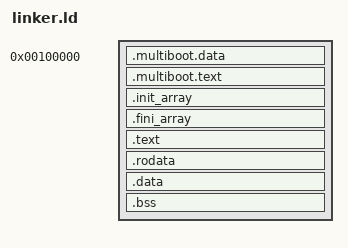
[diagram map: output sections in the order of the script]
ENTRY(_start)

SECTIONS
{
    . = 0x00100000;

    _kernel_start = .;
    .multiboot.data : {
        *(.multiboot.data)
    }

    .multiboot.text : {
        *(.multiboot.text)
    }

    .init_array : AT (ADDR(.init_array) - 0xC0000000)
    {
        crti.o(.init_array)
        KEEP (*(SORT(EXCLUDE_FILE(crti.o crtn.o) .init_array.*)))
        KEEP (*(EXCLUDE_FILE(crti.o crtn.o) .init_array))
        crtn.o(.init_array)
    }

    .fini_array : AT (ADDR(.fini_array) - 0xC0000000)
    {
        crti.o(.fini_array)
        KEEP (*(SORT(EXCLUDE_FILE(crti.o crtn.o) .fini_array.*)))
        KEEP (*(EXCLUDE_FILE(crti.o crtn.o) .fini_array))
        crtn.o(.fini_array)
    }

    . += 0xC0000000;

    .text ALIGN(4K) : AT (ADDR (.text) - 0xC0000000)
    {
        *(.text)
    }

    .rodata ALIGN(4K) : AT (ADDR (.rodata) - 0xC0000000)
    {
        *(.rodata)
    }

    .data ALIGN(4K) : AT (ADDR (.data) - 0xC0000000)
    {
        *(.data)
    }

    .bss ALIGN(4K) : AT (ADDR (.bss) - 0xC0000000)
    {
        *(COMMON)
        *(.bss)
        *(.bootstrap_stack)
    }

    _kernel_end = .;
}
